VERSION ""

NS_ :

BS_:

BU_: EON XXX INTERCEPTOR ANY ACTUATOR SAFETY

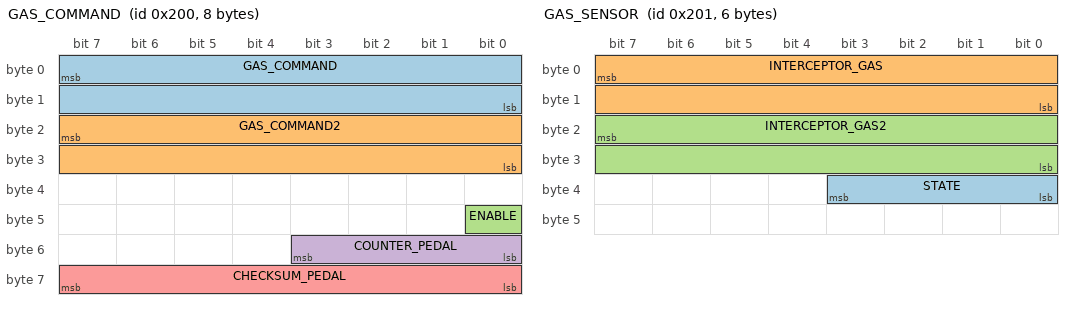
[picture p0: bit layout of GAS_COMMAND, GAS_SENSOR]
BO_ 512 GAS_COMMAND: 8 SAFETY
 SG_ GAS_COMMAND : 7|16@0+ (1,0) [0|1] "" ACTUATOR
 SG_ GAS_COMMAND2 : 23|16@0+ (1,0) [0|1] "" ACTUATOR
 SG_ ENABLE : 40|1@0+ (1,0) [0|1] "" ACTUATOR
 SG_ COUNTER_PEDAL : 51|4@0+ (1,0) [0|15] "" ACTUATOR
 SG_ CHECKSUM_PEDAL : 63|8@0+ (1,0) [0|255] "" ACTUATOR

BO_ 513 GAS_SENSOR: 6 ACTUATOR
 SG_ STATE : 35|4@0+ (1,0) [0|15] "" SAFETY
 SG_ INTERCEPTOR_GAS : 7|16@0+ (0.0007,-0.342) [0|1] "" SAFETY
 SG_ INTERCEPTOR_GAS2 : 23|16@0+ (0.0007,-0.691) [0|1] "" SAFETY

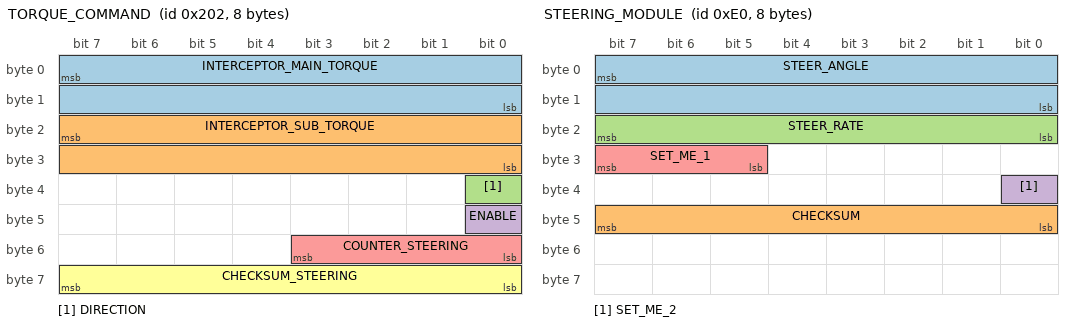
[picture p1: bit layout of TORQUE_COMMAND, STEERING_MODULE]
BO_ 514 TORQUE_COMMAND: 8 SAFETY
 SG_ INTERCEPTOR_MAIN_TORQUE : 7|16@0+ (1,0) [0|1] "" ACTUATOR
 SG_ INTERCEPTOR_SUB_TORQUE : 23|16@0+ (1,0) [0|1] "" ACTUATOR
 SG_ DIRECTION : 32|1@0+ (1,0) [0|1] "" ACTUATOR
 SG_ ENABLE : 40|1@0+ (1,0) [0|1] "" ACTUATOR
 SG_ COUNTER_STEERING : 51|4@0+ (1,0) [0|15] "" ACTUATOR
 SG_ CHECKSUM_STEERING : 63|8@0+ (1,0) [0|255] "" ACTUATOR

BO_ 224 STEERING_MODULE: 8 XXX
 SG_ STEER_ANGLE : 7|16@0- (0.1,0) [0|65535] "" XXX
 SG_ CHECKSUM : 47|8@0+ (1,0) [0|255] "" XXX
 SG_ STEER_RATE : 23|8@0+ (1,0) [0|255] "" XXX
 SG_ SET_ME_2 : 32|1@0+ (1,0) [0|1] "" XXX
 SG_ SET_ME_1 : 31|3@0+ (1,0) [0|7] "" XXX

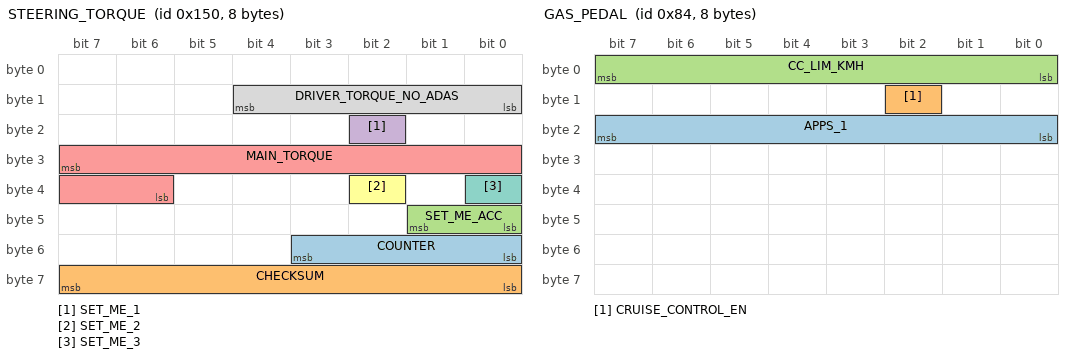
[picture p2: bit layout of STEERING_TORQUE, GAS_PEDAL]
BO_ 336 STEERING_TORQUE: 8 XXX
 SG_ COUNTER : 48|4@1+ (1,0) [0|15] "" XXX
 SG_ CHECKSUM : 56|8@1+ (1,0) [0|255] "" XXX
 SG_ SET_ME_ACC : 40|2@1+ (1,0) [0|3] "" XXX
 SG_ SET_ME_1 : 18|1@0+ (1,0) [0|1] "" XXX
 SG_ MAIN_TORQUE : 31|10@0+ (1,0) [0|1023] "" XXX
 SG_ SET_ME_2 : 34|1@1+ (1,0) [0|7] "" XXX
 SG_ SET_ME_3 : 32|1@0+ (1,0) [0|1] "" XXX
 SG_ DRIVER_TORQUE_NO_ADAS : 8|5@1+ (1,0) [0|31] "" XXX

BO_ 291 BRAKE: 8 XXX
 SG_ BRAKE_PRESSURE : 39|16@0+ (0.0002,0) [0|65535] "" XXX

BO_ 294 FCW: 8 XXX
 SG_ STOCK_FCW_TRIGGERED : 5|1@0+ (1,0) [0|1] "" XXX

BO_ 130 ENGINE: 8 XXX
 SG_ BRAKE_ENGAGED : 35|1@0+ (1,0) [0|1] "" XXX

BO_ 132 GAS_PEDAL: 8 XXX
 SG_ APPS_1 : 23|8@0+ (0.004,0) [0|255] "" XXX
 SG_ CRUISE_CONTROL_EN : 10|1@0+ (1,0) [0|1] "" XXX
 SG_ CC_LIM_KMH : 7|8@0+ (1,0) [0|255] "" XXX

BO_ 641 LEFT_STALK: 8 XXX
 SG_ LEFT_SIGNAL : 16|1@0+ (1,0) [0|1] "" XXX
 SG_ RIGHT_SIGNAL : 17|1@0+ (1,0) [0|1] "" XXX
 SG_ LIGHT_AUTO : 26|1@0+ (1,0) [0|1] "" XXX
 SG_ LOW_BEAM : 4|1@0+ (1,0) [0|1] "" XXX
 SG_ AUTO_HIGH_BEAM_TOGGLE : 33|1@0+ (1,0) [0|1] "" XXX
 SG_ POSITION_LAMP : 24|1@0+ (1,0) [0|1] "" XXX
 SG_ FLASH_HIGH_BEAM : 14|1@0+ (1,0) [0|1] "" XXX
 SG_ GENERIC_TOGGLE : 6|1@0+ (1,0) [0|511] "" XXX
 SG_ WASHER_FRONT : 2|1@0+ (1,0) [0|1] "" XXX
 SG_ WASHER_REAR : 0|1@0+ (1,0) [0|1] "" XXX
 SG_ WIPER_AUTO : 13|1@0+ (1,0) [0|1] "" XXX
 SG_ WIPER_FAST : 12|1@0+ (1,0) [0|1] "" XXX
 SG_ WIPER_SLOW : 11|1@0+ (1,0) [0|1] "" XXX
 SG_ WIPER_SPEED : 8|5@1+ (1,0) [0|7] "" XXX
 SG_ WIPER_REAR_SLOW : 19|1@0+ (1,0) [0|1] "" XXX
 SG_ WIPER_REAR_FAST : 18|1@0+ (1,0) [0|1] "" XXX

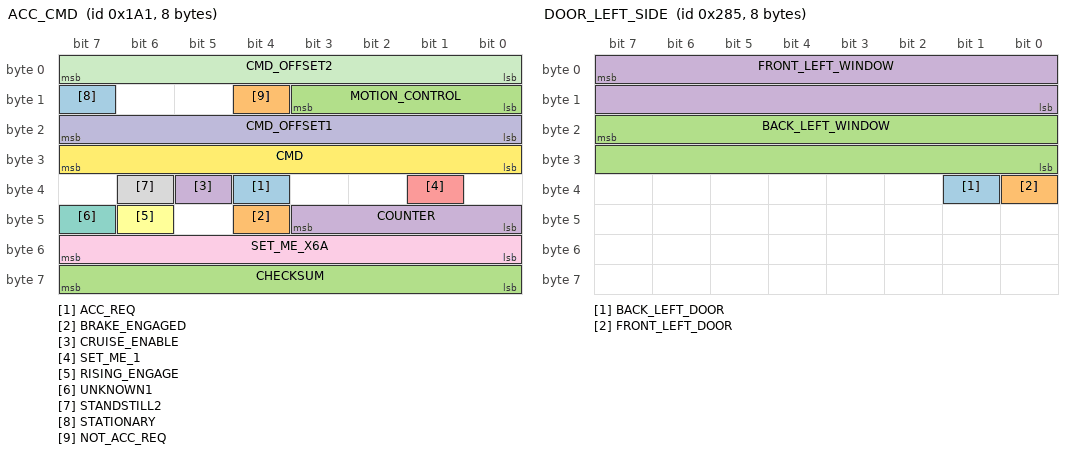
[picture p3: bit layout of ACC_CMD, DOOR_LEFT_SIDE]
BO_ 417 ACC_CMD: 8 XXX
 SG_ ACC_REQ : 36|1@0+ (1,0) [0|31] "" XXX
 SG_ BRAKE_ENGAGED : 44|1@0+ (1,0) [0|1] "" XXX
 SG_ CHECKSUM : 56|8@1+ (1,0) [0|255] "" XXX
 SG_ CRUISE_ENABLE : 37|1@0+ (1,0) [0|1] "" XXX
 SG_ SET_ME_1 : 33|1@0+ (1,0) [0|1] "" XXX
 SG_ RISING_ENGAGE : 46|1@0+ (1,0) [0|1] "" XXX
 SG_ UNKNOWN1 : 47|1@0+ (1,0) [0|1] "" XXX
 SG_ STANDSTILL2 : 38|1@0+ (1,0) [0|1] "" XXX
 SG_ SET_ME_X6A : 55|8@0+ (1,0) [0|255] "" XXX
 SG_ CMD_OFFSET1 : 23|8@0+ (1,-142) [0|255] "" XXX
 SG_ CMD_OFFSET2 : 7|8@0+ (1,-140) [0|255] "" XXX
 SG_ CMD : 31|8@0+ (1,-138) [0|255] "" XXX
 SG_ STATIONARY : 15|1@0+ (1,0) [0|1] "" XXX
 SG_ NOT_ACC_REQ : 12|1@0+ (1,0) [0|1] "" XXX
 SG_ MOTION_CONTROL : 8|4@1+ (1,0) [0|15] "" XXX
 SG_ COUNTER : 40|4@1+ (1,0) [0|15] "" XXX

BO_ 645 DOOR_LEFT_SIDE: 8 XXX
 SG_ BACK_LEFT_DOOR : 33|1@0+ (1,0) [0|511] "" XXX
 SG_ FRONT_LEFT_DOOR : 32|1@0+ (1,0) [0|511] "" XXX
 SG_ BACK_LEFT_WINDOW : 23|16@0+ (0.000019422,0) [0|65535] "" XXX
 SG_ FRONT_LEFT_WINDOW : 7|16@0+ (1,0) [0|65535] "" XXX

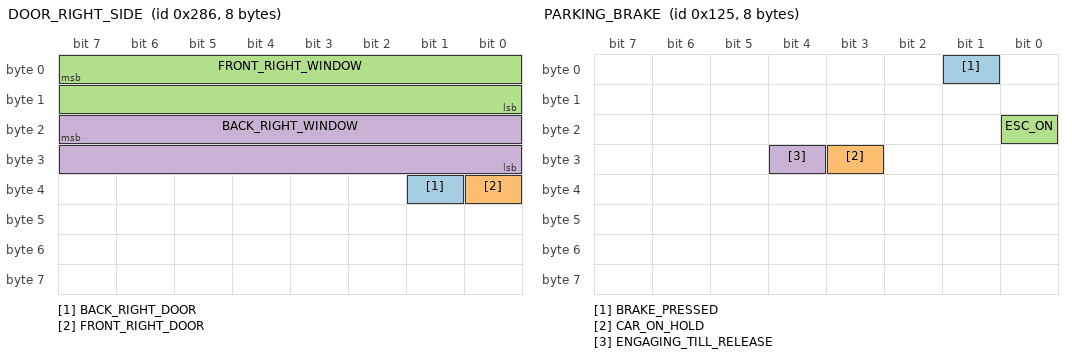
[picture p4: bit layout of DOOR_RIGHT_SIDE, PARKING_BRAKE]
BO_ 646 DOOR_RIGHT_SIDE: 8 XXX
 SG_ BACK_RIGHT_DOOR : 33|1@0+ (1,0) [0|1] "" XXX
 SG_ FRONT_RIGHT_DOOR : 32|1@0+ (1,0) [0|511] "" XXX
 SG_ FRONT_RIGHT_WINDOW : 7|16@0+ (0.000019422,0) [0|65535] "" XXX
 SG_ BACK_RIGHT_WINDOW : 23|16@0+ (0.000019422,0) [0|65535] "" XXX

BO_ 896 SEATBELTS: 8 XXX
 SG_ RIGHT_SIDE_SEATBELT_ACTIVE_LOW : 0|1@0+ (1,0) [0|1] "" XXX
 SG_ LEFT_SIDE_SEATBELT_ACTIVE_LOW : 1|1@0+ (1,0) [0|1] "" XXX

BO_ 293 PARKING_BRAKE: 8 XXX
 SG_ BRAKE_PRESSED : 1|1@0+ (1,0) [0|1] "" XXX
 SG_ CAR_ON_HOLD : 27|1@0+ (1,0) [0|1] "" XXX
 SG_ ESC_ON : 16|1@0+ (1,0) [0|1] "" XXX
 SG_ ENGAGING_TILL_RELEASE : 28|1@0+ (1,0) [0|1] "" XXX

BO_ 275 TRANSMISSION: 8 XXX
 SG_ GEAR : 39|4@0+ (1,0) [0|255] "" XXX

BO_ 290 WHEEL_SPEED: 8 XXX
 SG_ WHEELSPEED_B : 23|16@0+ (0.007,0) [0|65535] "" XXX
 SG_ WHEELSPEED_F : 7|16@0+ (0.007,0) [0|65535] "" XXX

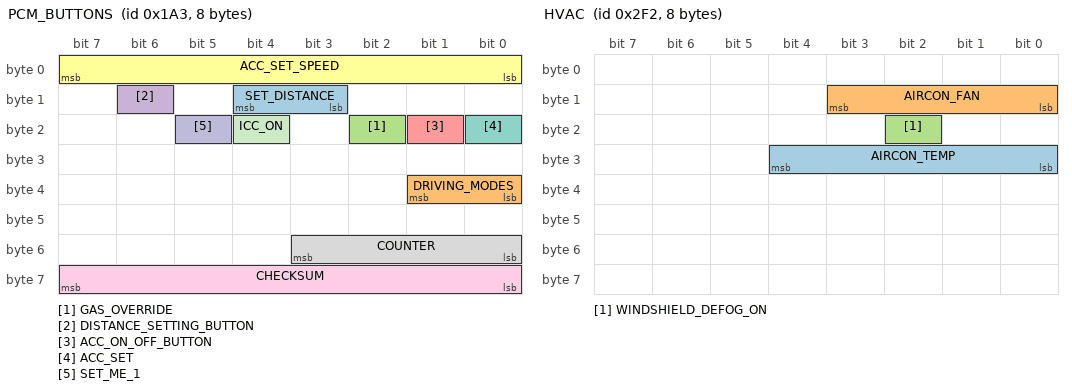
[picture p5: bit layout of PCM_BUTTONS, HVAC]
BO_ 419 PCM_BUTTONS: 8 XXX
 SG_ SET_DISTANCE : 12|2@0+ (1,0) [0|3] "" XXX
 SG_ DRIVING_MODES : 33|2@0+ (1,0) [0|3] "" XXX
 SG_ GAS_OVERRIDE : 18|1@0+ (1,0) [0|1] "" XXX
 SG_ DISTANCE_SETTING_BUTTON : 14|1@0+ (1,0) [0|1] "" XXX
 SG_ ACC_ON_OFF_BUTTON : 17|1@0+ (1,0) [0|1] "" XXX
 SG_ ACC_SET_SPEED : 7|8@0+ (1,0) [0|255] "" XXX
 SG_ ACC_SET : 16|1@0+ (1,0) [0|1] "" XXX
 SG_ COUNTER : 48|4@1+ (1,0) [0|15] "" XXX
 SG_ CHECKSUM : 56|8@1+ (1,0) [0|255] "" XXX
 SG_ SET_ME_1 : 21|1@0+ (1,0) [0|3] "" XXX
 SG_ ICC_ON : 20|1@0+ (1,0) [0|1] "" XXX

BO_ 676 POWER_MODE: 8 XXX
 SG_ MODE : 15|2@0+ (1,0) [0|3] "" XXX

BO_ 753 AIRCON: 8 XXX
 SG_ AC_ON : 2|1@0+ (1,0) [0|511] "" XXX

BO_ 754 HVAC: 8 XXX
 SG_ AIRCON_TEMP : 24|5@1+ (1,0) [0|15] "" XXX
 SG_ AIRCON_FAN : 8|4@1+ (1,0) [0|15] "" XXX
 SG_ WINDSHIELD_DEFOG_ON : 18|1@0+ (1,0) [0|1] "" XXX

BO_ 528 WHEELSPEED: 8 XXX
 SG_ WHEELSPEED_FRONT : 7|16@0+ (0.0088,-0.0704) [0|16777215] "" XXX
 SG_ WHEELSPEED_BACK : 23|16@0+ (0.0011,-0.0704) [0|65535] "" XXX

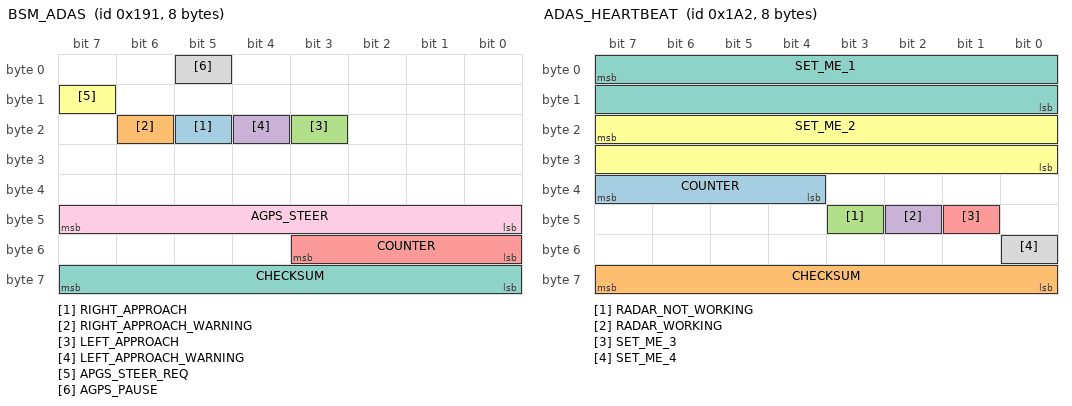
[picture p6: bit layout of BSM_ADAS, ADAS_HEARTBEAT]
BO_ 401 BSM_ADAS: 8 XXX
 SG_ RIGHT_APPROACH : 21|1@0+ (1,0) [0|1] "" XXX
 SG_ RIGHT_APPROACH_WARNING : 22|1@0+ (1,0) [0|1] "" XXX
 SG_ LEFT_APPROACH : 19|1@0+ (1,0) [0|1] "" XXX
 SG_ LEFT_APPROACH_WARNING : 20|1@0+ (1,0) [0|1] "" XXX
 SG_ COUNTER : 48|4@1+ (1,0) [0|15] "" XXX
 SG_ APGS_STEER_REQ : 15|1@0+ (1,0) [0|1] "" XXX
 SG_ CHECKSUM : 63|8@0+ (1,0) [0|255] "" XXX
 SG_ AGPS_PAUSE : 5|1@0+ (1,0) [0|1] "" XXX
 SG_ AGPS_STEER : 47|8@0+ (1,0) [0|255] "" XXX

BO_ 418 ADAS_HEARTBEAT: 8 XXX
 SG_ COUNTER : 39|4@0+ (1,0) [0|15] "" XXX
 SG_ CHECKSUM : 63|8@0+ (1,0) [0|255] "" XXX
 SG_ RADAR_NOT_WORKING : 43|1@0+ (1,0) [0|1] "" XXX
 SG_ RADAR_WORKING : 42|1@0+ (1,0) [0|1] "" XXX
 SG_ SET_ME_3 : 41|1@0+ (1,0) [0|1] "" XXX
 SG_ SET_ME_2 : 23|16@0+ (1,0) [0|65535] "" XXX
 SG_ SET_ME_1 : 7|16@0+ (1,0) [0|65535] "" XXX
 SG_ SET_ME_4 : 48|1@0+ (1,0) [0|1] "" XXX

BO_ 432 ADAS_LKAS: 8 XXX
 SG_ HAND_ON_WHEEL_WARNING : 34|1@0+ (1,0) [0|1] "" XXX
 SG_ WHEEL_WARNING_CHIME : 35|1@0+ (1,0) [0|1] "" XXX
 SG_ CHECKSUM : 63|8@0+ (1,0) [0|255] "" XXX
 SG_ COUNTER : 48|4@1+ (1,0) [0|15] "" XXX
 SG_ LKAS_LINE_ACTIVE : 25|1@0+ (1,0) [0|1] "" XXX
 SG_ LKAS_ENGAGED1 : 12|1@0+ (1,0) [0|1] "" XXX
 SG_ LKA_ENABLE : 13|1@0+ (1,0) [0|1] "" XXX
 SG_ LKS_STATUS : 24|1@0+ (1,0) [0|1] "" XXX
 SG_ STOCK_LKS_AUX : 19|1@0+ (1,0) [0|1] "" XXX
 SG_ LKS_WARNING_AUDIO_TYPE : 22|1@0+ (1,0) [0|1] "" XXX
 SG_ LKS_WARNING_TACTILE_TYPE : 23|1@0+ (1,0) [0|1] "" XXX
 SG_ LKS_ASSIST_MODE : 20|1@0+ (1,0) [0|1] "" XXX
 SG_ STEER_CMD : 47|11@0+ (1,0) [0|598] "" XXX
 SG_ STEER_DIR : 52|1@0+ (1,0) [0|1] "" XXX
 SG_ LDW_READY : 0|1@0+ (1,0) [0|1] "" XXX
 SG_ SET_ME_1 : 9|1@0+ (1,0) [0|1] "" XXX
 SG_ LDW_STEERING : 4|1@0+ (1,0) [0|1] "" XXX

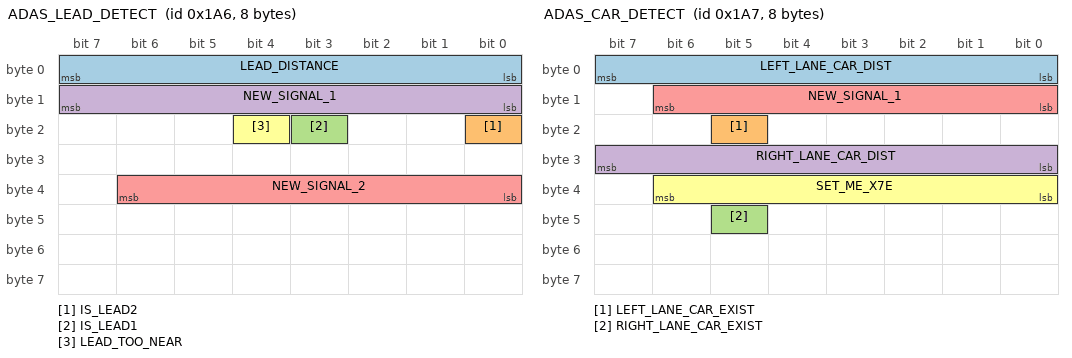
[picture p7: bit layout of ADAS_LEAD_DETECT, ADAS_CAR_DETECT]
BO_ 422 ADAS_LEAD_DETECT: 8 XXX
 SG_ LEAD_DISTANCE : 7|8@0+ (1,0) [0|255] "" XXX
 SG_ IS_LEAD2 : 16|1@0+ (1,0) [0|1] "" XXX
 SG_ IS_LEAD1 : 19|1@0+ (1,0) [0|1] "" XXX
 SG_ NEW_SIGNAL_1 : 15|8@0+ (1,0) [0|255] "" XXX
 SG_ NEW_SIGNAL_2 : 38|7@0+ (1,0) [0|255] "" XXX
 SG_ LEAD_TOO_NEAR : 20|1@0+ (1,0) [0|1] "" XXX

BO_ 423 ADAS_CAR_DETECT: 8 XXX
 SG_ LEFT_LANE_CAR_DIST : 7|8@0+ (1,0) [0|255] "" XXX
 SG_ LEFT_LANE_CAR_EXIST : 21|1@0+ (1,0) [0|1] "" XXX
 SG_ RIGHT_LANE_CAR_EXIST : 45|1@0+ (1,0) [0|1] "" XXX
 SG_ RIGHT_LANE_CAR_DIST : 31|8@0+ (1,0) [0|255] "" XXX
 SG_ NEW_SIGNAL_1 : 14|7@0+ (1,-126) [0|255] "" XXX
 SG_ SET_ME_X7E : 38|7@0+ (1,-126) [0|127] "" XXX

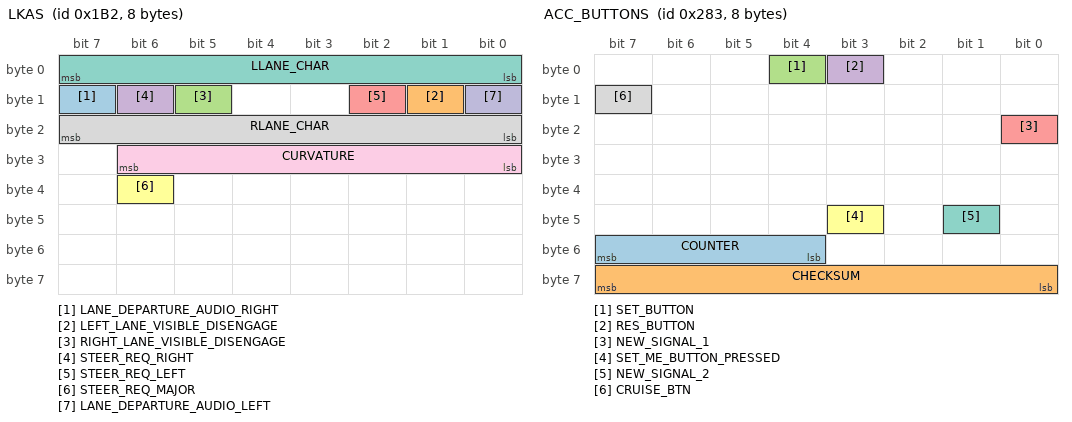
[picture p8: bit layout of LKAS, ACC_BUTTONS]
BO_ 434 LKAS: 8 XXX
 SG_ LANE_DEPARTURE_AUDIO_RIGHT : 15|1@0+ (1,0) [0|1] "" XXX
 SG_ LEFT_LANE_VISIBLE_DISENGAGE : 9|1@0+ (1,0) [0|1] "" XXX
 SG_ RIGHT_LANE_VISIBLE_DISENGAGE : 13|1@0+ (1,0) [0|1] "" XXX
 SG_ STEER_REQ_RIGHT : 14|1@0+ (1,0) [0|1] "" XXX
 SG_ STEER_REQ_LEFT : 10|1@0+ (1,0) [0|1] "" XXX
 SG_ STEER_REQ_MAJOR : 38|1@0+ (1,0) [0|1] "" XXX
 SG_ LLANE_CHAR : 0|8@1- (1,0) [0|255] "" XXX
 SG_ RLANE_CHAR : 23|8@0+ (1,0) [0|255] "" XXX
 SG_ CURVATURE : 30|7@0- (1,0) [0|127] "" XXX
 SG_ LANE_DEPARTURE_AUDIO_LEFT : 8|1@0+ (1,0) [0|1] "" XXX

BO_ 643 ACC_BUTTONS: 8 XXX
 SG_ COUNTER : 55|4@0+ (1,0) [0|15] "" XXX
 SG_ CHECKSUM : 56|8@1+ (1,0) [0|255] "" XXX
 SG_ SET_BUTTON : 4|1@0+ (1,0) [0|1] "" XXX
 SG_ RES_BUTTON : 3|1@0+ (1,0) [0|1] "" XXX
 SG_ NEW_SIGNAL_1 : 16|1@0+ (1,0) [0|1] "" XXX
 SG_ SET_ME_BUTTON_PRESSED : 43|1@0+ (1,0) [0|1] "" XXX
 SG_ NEW_SIGNAL_2 : 41|1@0+ (1,0) [0|1] "" XXX
 SG_ CRUISE_BTN : 15|1@0+ (1,0) [0|1] "" XXX

VAL_ 275 GEAR 15 "D" 14 "D" 13 "D" 12 "D" 11 "R" 10 "P" 9 "D" 8 "D" 7 "D" 6 "D" 5 "D" 4 "D" 3 "D" 2 "D" 1 "D" 0 "N" ;
VAL_ 419 SET_DISTANCE 3 "3BAR" 2 "2BAR" 1 "1BAR" ;
VAL_ 676 MODE 2 "NORMAL" 1 "SPORT" 0 "ECO" ;

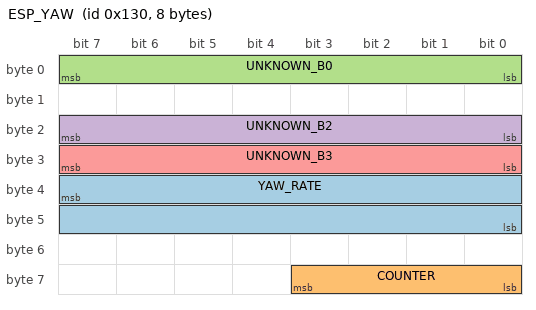
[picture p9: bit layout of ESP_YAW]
BO_ 304 ESP_YAW: 8 XXX
 SG_ YAW_RATE : 39|16@0+ (0.01,-179.73) [-30|30] "deg/s" XXX
 SG_ COUNTER : 59|4@0+ (1,0) [0|15] "" XXX
 SG_ UNKNOWN_B0 : 7|8@0+ (1,0) [0|255] "" XXX
 SG_ UNKNOWN_B2 : 23|8@0+ (1,0) [0|255] "" XXX
 SG_ UNKNOWN_B3 : 31|8@0+ (1,0) [0|255] "" XXX
CM_ BO_ 304 "0x130 ESP偏航率, bus0 50Hz. 逆向2026-07-21: 雷达g1.b5横向速度反推偏航率扫车身总线发现, r=-0.99";
CM_ SG_ 304 YAW_RATE "零点raw=17973. 与雷达FRS(0x080)Host_Yaw回归斜率1.00(r=0.997); vs方向盘0x0e0 r=+0.70~0.81";
